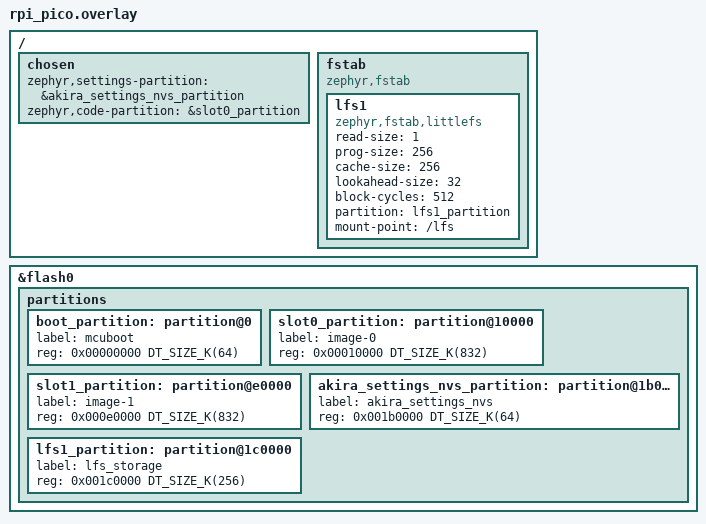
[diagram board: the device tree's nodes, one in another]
/*
 * Raspberry Pi Pico (RP2040) DTS overlay for AkiraOS
 * Board: rpi_pico
 *
 * The upstream rpi_pico board in Zephyr already defines:
 *   - GPIO (26 pins), SPI0/1, I2C0/1, ADC, PWM, USB
 * This overlay adds AkiraOS-specific storage partitioning only.
 */

/*
 * RP2040 has 2 MB external QSPI flash (&flash0). AkiraOS builds MCUboot images
 * (CONFIG_BOOTLOADER_MCUBOOT=y), so mirror the upstream MCUboot partitioning
 * (see partitions_2M_sysbuild.dtsi): the boot_partition@0 subsumes the 256-byte
 * second-stage bootloader, and the app is linked into slot0. Delete the base
 * full-flash code_partition first, then add equal slot0/slot1 + AkiraOS
 * settings-NVS + LittleFS.
 */
/delete-node/ &code_partition;

&flash0 {
    partitions {
        boot_partition: partition@0 {
            label = "mcuboot";
            reg = <0x00000000 DT_SIZE_K(64)>;
        };

        slot0_partition: partition@10000 {
            label = "image-0";
            reg = <0x00010000 DT_SIZE_K(832)>;
        };

        slot1_partition: partition@e0000 {
            label = "image-1";
            reg = <0x000e0000 DT_SIZE_K(832)>;
        };

        akira_settings_nvs_partition: partition@1b0000 {
            label = "akira_settings_nvs";
            reg = <0x001b0000 DT_SIZE_K(64)>;
        };

        lfs1_partition: partition@1c0000 {
            label = "lfs_storage";
            reg = <0x001c0000 DT_SIZE_K(256)>;
        };
    };
};

/ {
    chosen {
        zephyr,settings-partition = &akira_settings_nvs_partition;
        zephyr,code-partition = &slot0_partition;
    };

    fstab {
        compatible = "zephyr,fstab";

        lfs1: lfs1 {
            compatible = "zephyr,fstab,littlefs";
            read-size = <1>;
            prog-size = <256>;
            cache-size = <256>;
            lookahead-size = <32>;
            block-cycles = <512>;
            partition = <&lfs1_partition>;
            mount-point = "/lfs";
        };
    };
};
